# CTRL_MMR0_CTRL_MMR0_STATUS_MMRS_09300000h register map
Vendor: Texas Instruments
Peripheral module from a debugger description file (folder am62L).
Registers are 32-bit, read-only, reset 0x0 unless marked. A register's access mark holds for its fields unless they carry their own. Offsets are as the file gives them; lines under a group give offsets from that group; [hi:lo] are bit positions; {n}, {i} and the like mark numbered series; 'fields as' and 'values as' point back to an identical list; <NAME> marks a mode.

## CTRL_MMR0_STATUS_MMRS
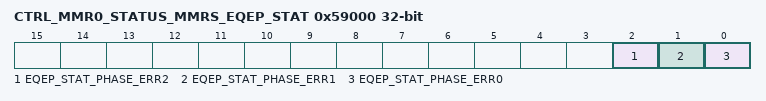
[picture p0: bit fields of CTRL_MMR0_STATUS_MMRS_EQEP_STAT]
0x59000 CTRL_MMR0_STATUS_MMRS_EQEP_STAT — Displays status of EQEP modules
  [2] EQEP_STAT_PHASE_ERR2 — EQEP2 Phase error statusField values (others are reserved):1'b0 - NO_ERROR1'b1 - PHASE_ERROR Reset Source: mod_g_rst_n
  [1] EQEP_STAT_PHASE_ERR1 — EQEP1 Phase error statusField values (others are reserved):1'b0 - NO_ERROR1'b1 - PHASE_ERROR Reset Source: mod_g_rst_n
  [0] EQEP_STAT_PHASE_ERR0 — EQEP0 Phase error statusField values (others are reserved):1'b0 - NO_ERROR1'b1 - PHASE_ERROR Reset Source: mod_g_rst_n
